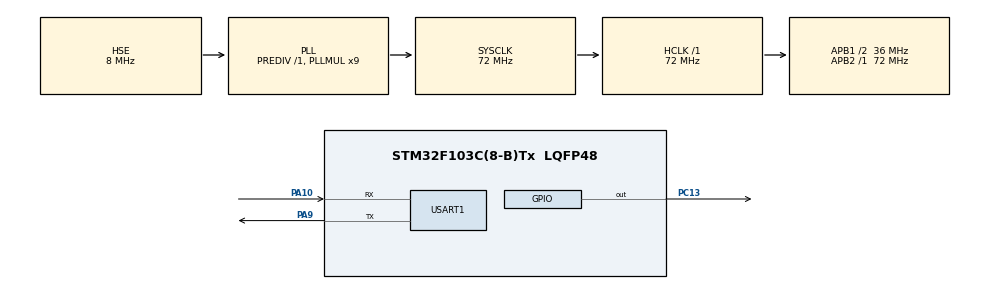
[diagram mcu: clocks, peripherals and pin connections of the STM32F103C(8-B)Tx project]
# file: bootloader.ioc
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Mcu.Family=STM32F1
Mcu.Name=STM32F103C(8-B)Tx
Mcu.Package=LQFP48
NVIC.PriorityGroup=NVIC_PRIORITYGROUP_4
PA10.Mode=Asynchronous
PA10.Signal=USART1_RX
PA9.Mode=Asynchronous
PA9.Signal=USART1_TX
PC13-TAMPER-RTC.Signal=GPIO_Output
PD0-OSC_IN.Mode=HSE-External-Oscillator
PD0-OSC_IN.Signal=RCC_OSC_IN
PD1-OSC_OUT.Mode=HSE-External-Oscillator
PD1-OSC_OUT.Signal=RCC_OSC_OUT
ProjectManager.HeapSize=0x200
ProjectManager.StackSize=0x400
ProjectManager.TargetToolchain=STM32CubeIDE
RCC.AHBFreq_Value=72000000
RCC.APB1CLKDivider=RCC_HCLK_DIV2
RCC.APB1Freq_Value=36000000
RCC.APB1TimFreq_Value=72000000
RCC.APB2Freq_Value=72000000
RCC.APB2TimFreq_Value=72000000
RCC.HCLKFreq_Value=72000000
RCC.PLLMUL=RCC_PLL_MUL9
RCC.PLLSourceVirtual=RCC_PLLSOURCE_HSE
RCC.SYSCLKFreq_VALUE=72000000
RCC.SYSCLKSource=RCC_SYSCLKSOURCE_PLLCLK
RCC.USBFreq_Value=72000000
USART1.VirtualMode=VM_ASYNC
VP_CRC_VS_CRC.Mode=CRC_Activate
VP_SYS_VS_ND.Mode=No_Debug
board=custom

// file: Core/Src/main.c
/* USER CODE BEGIN Header */
/**
  ******************************************************************************
  * @file           : main.c
  * @brief          : Main program body
  ******************************************************************************
  * @attention
  *
  * Copyright (c) 2026 STMicroelectronics.
  * All rights reserved.
  *
  * This software is licensed under terms that can be found in the LICENSE file
  * in the root directory of this software component.
  * If no LICENSE file comes with this software, it is provided AS-IS.
  *
  ******************************************************************************
  */
/* USER CODE END Header */
#include "main.h"

/* USER CODE BEGIN Includes */
#include <stdio.h>
#include <string.h>
#include <math.h>
#include "flash_layout.h"
#include "app_header.h"
#include "flash_operations.h"
/* USER CODE END Includes */

/* USER CODE BEGIN PTD */
typedef void (*p_func)(void);
/* USER CODE END PTD */

/* USER CODE BEGIN PD */
#define MAGIC_NUM_ERR		"Magic number error\r\n"
#define RESET_HANDLER_ERR	"Reset handler error\r\n"
#define CRC_ERR				"CRC check error\r\n"
/* USER CODE END PD */

CRC_HandleTypeDef hcrc;

UART_HandleTypeDef huart1;

void SystemClock_Config(void);
static void MX_GPIO_Init(void);
static void MX_USART1_UART_Init(void);
static void MX_CRC_Init(void);
/* USER CODE BEGIN PFP */
void jump_to_application(void);
int is_application_not_valid(void);
/* USER CODE END PFP */

int main(void)
{

  /* MCU Configuration--------------------------------------------------------*/

  /* Reset of all peripherals, Initializes the Flash interface and the Systick. */
  HAL_Init();

  /* Configure the system clock */
  SystemClock_Config();

  /* Initialize all configured peripherals */
  MX_GPIO_Init();
  MX_USART1_UART_Init();
  MX_CRC_Init();
  /* USER CODE BEGIN 2 */
//  __disable_irq();

//  uint32_t primask = __get_PRIMASK();
//  HAL_UART_Transmit(&huart1, (uint8_t *)"This is a test message\r\n", 24, 1000);
//  HAL_Delay(1);
//  uint8_t message[100] = {'\0'};
//  sprintf((char *)message, "PRIMASK VALUE: %lu", primask);
//  HAL_UART_Transmit(&huart1, message, sizeof(message), 1000);
//
//  __enable_irq();
//  primask = __get_PRIMASK();
//  sprintf((char *)message, "PRIMASK VALUE AFTER ENABLING: %lu", primask);
//  HAL_UART_Transmit(&huart1, message, sizeof(message), 1000);

  HAL_UART_Transmit(&huart1, (uint8_t *)"Hello from the bootloader\r\n", 27, HAL_MAX_DELAY);

  int application_validation_status = is_application_not_valid();
  if (application_validation_status != 0) {
	  switch (application_validation_status) {
	  case 1:
		  HAL_UART_Transmit(&huart1, (uint8_t *)MAGIC_NUM_ERR, strlen(MAGIC_NUM_ERR), HAL_MAX_DELAY);
		  break;
	  case 2:
		  HAL_UART_Transmit(&huart1, (uint8_t *)RESET_HANDLER_ERR, strlen(RESET_HANDLER_ERR), HAL_MAX_DELAY);
		  break;
	  case 3:
		  HAL_UART_Transmit(&huart1, (uint8_t *)CRC_ERR, strlen(CRC_ERR), HAL_MAX_DELAY);

		  /* First, erase the application memory */
		  erase_application_pages();

		  /* Write the Active Slot with the Backup Image */
		  write_application_into_flash();

		  /* Perform a software system reset */
		  NVIC_SystemReset();

		  break;
	  }

	  while(1) {
		  HAL_GPIO_TogglePin(GPIOC, GPIO_PIN_13);
		  HAL_Delay(500);
	  }
  }

  jump_to_application();
  /* USER CODE END 2 */

  /* Infinite loop */
  while (1)
  {

  }
}

void SystemClock_Config(void)
{
  RCC_OscInitTypeDef RCC_OscInitStruct = {0};
  RCC_ClkInitTypeDef RCC_ClkInitStruct = {0};

  /** Initializes the RCC Oscillators according to the specified parameters
  * in the RCC_OscInitTypeDef structure.
  */
  RCC_OscInitStruct.OscillatorType = RCC_OSCILLATORTYPE_HSE;
  RCC_OscInitStruct.HSEState = RCC_HSE_ON;
  RCC_OscInitStruct.HSEPredivValue = RCC_HSE_PREDIV_DIV1;
  RCC_OscInitStruct.HSIState = RCC_HSI_ON;
  RCC_OscInitStruct.PLL.PLLState = RCC_PLL_ON;
  RCC_OscInitStruct.PLL.PLLSource = RCC_PLLSOURCE_HSE;
  RCC_OscInitStruct.PLL.PLLMUL = RCC_PLL_MUL9;
  if (HAL_RCC_OscConfig(&RCC_OscInitStruct) != HAL_OK)
  {
    Error_Handler();
  }

  /** Initializes the CPU, AHB and APB buses clocks
  */
  RCC_ClkInitStruct.ClockType = RCC_CLOCKTYPE_HCLK|RCC_CLOCKTYPE_SYSCLK
                              |RCC_CLOCKTYPE_PCLK1|RCC_CLOCKTYPE_PCLK2;
  RCC_ClkInitStruct.SYSCLKSource = RCC_SYSCLKSOURCE_PLLCLK;
  RCC_ClkInitStruct.AHBCLKDivider = RCC_SYSCLK_DIV1;
  RCC_ClkInitStruct.APB1CLKDivider = RCC_HCLK_DIV2;
  RCC_ClkInitStruct.APB2CLKDivider = RCC_HCLK_DIV1;

  if (HAL_RCC_ClockConfig(&RCC_ClkInitStruct, FLASH_LATENCY_2) != HAL_OK)
  {
    Error_Handler();
  }
}

static void MX_CRC_Init(void)
{

  hcrc.Instance = CRC;
  if (HAL_CRC_Init(&hcrc) != HAL_OK)
  {
    Error_Handler();
  }
  /* USER CODE BEGIN CRC_Init 2 */
  __HAL_RCC_CRC_CLK_ENABLE();
  /* USER CODE END CRC_Init 2 */

}

static void MX_USART1_UART_Init(void)
{

  huart1.Instance = USART1;
  huart1.Init.BaudRate = 115200;
  huart1.Init.WordLength = UART_WORDLENGTH_8B;
  huart1.Init.StopBits = UART_STOPBITS_1;
  huart1.Init.Parity = UART_PARITY_NONE;
  huart1.Init.Mode = UART_MODE_TX_RX;
  huart1.Init.HwFlowCtl = UART_HWCONTROL_NONE;
  huart1.Init.OverSampling = UART_OVERSAMPLING_16;
  if (HAL_UART_Init(&huart1) != HAL_OK)
  {
    Error_Handler();
  }

}

static void MX_GPIO_Init(void)
{
  GPIO_InitTypeDef GPIO_InitStruct = {0};

  /* GPIO Ports Clock Enable */
  __HAL_RCC_GPIOC_CLK_ENABLE();
  __HAL_RCC_GPIOD_CLK_ENABLE();
  __HAL_RCC_GPIOA_CLK_ENABLE();

  /*Configure GPIO pin Output Level */
  HAL_GPIO_WritePin(GPIOC, GPIO_PIN_13, GPIO_PIN_RESET);

  /*Configure GPIO pin : PC13 */
  GPIO_InitStruct.Pin = GPIO_PIN_13;
  GPIO_InitStruct.Mode = GPIO_MODE_OUTPUT_PP;
  GPIO_InitStruct.Pull = GPIO_NOPULL;
  GPIO_InitStruct.Speed = GPIO_SPEED_FREQ_LOW;
  HAL_GPIO_Init(GPIOC, &GPIO_InitStruct);

}

/* USER CODE BEGIN 4 */
void jump_to_application(void) {
	uint32_t app_top_of_stack = *(uint32_t *)APP_START_ADDR;
	uint32_t app_reset_handler_ptr = *(uint32_t *)(APP_START_ADDR + 4);

	p_func app_entry = (p_func)app_reset_handler_ptr;

	__disable_irq();

	SysTick->CTRL = 0ul;
	SysTick->LOAD = 0ul;
	SysTick->VAL = 0ul;

	__set_MSP(app_top_of_stack);

	app_entry();
}

int is_application_not_valid(void) {
	const app_header_t *app_header = (const app_header_t *) APP_HEADER_START_ADDR;
	const uint32_t app_magic_number = (uint32_t) APP_MAGIC_NUMBER;

	if (app_header->magic_number != app_magic_number) {
		return 1;
	}

	const uint32_t reset_handler = *(uint32_t *) (APP_START_ADDR + 4);
	if ((reset_handler & 0xFF000000) != 0x08000000) {
		return 2;
	}

	uint32_t *application_start_addr = (uint32_t *) APP_START_ADDR;
	uint32_t number_of_words = ceil(app_header->app_size / 4.0);					// number of 32-bit words. Since the pointer to memory is a 32-bit pointer.

	uint32_t crc = HAL_CRC_Calculate(&hcrc, application_start_addr, number_of_words);
	if (crc != app_header->crc) {
		return 3;
	}

	return 0;
}
/* USER CODE END 4 */

void Error_Handler(void)
{
  __disable_irq();
  while (1)
  {
  }
}
